# Cortex_M0 register map
Vendor: ARM Ltd.; File version: 1.1
Cortex-M0 core descriptions, generated from ARM develloper studio
CPU: CM0 r0p0, little endian, no MPU, no FPU, vendor SysTick, 8 interrupt priority bits
Registers are 32-bit, read-write, no defined reset value unless marked. A register's access mark holds for its fields unless they carry their own. Offsets are from the block's base; lines under a group give offsets from that group; [hi:lo] are bit positions; {n}, {i} and the like mark numbered series; 'fields as' and 'values as' point back to an identical list; <NAME> marks a mode.

## Memory map
0xE000E010 SysTick size 0x80 — System Timer registers
0xE000E100 NVIC size 0x1A0 — Nested Vectored Interrupt Controller registers
0xE000ED00 ID size 0x20 — ID registers
0xE000ED04 Control size 0xC0 — System Control registers

## Control — System Control registers
Base 0xE000ED04
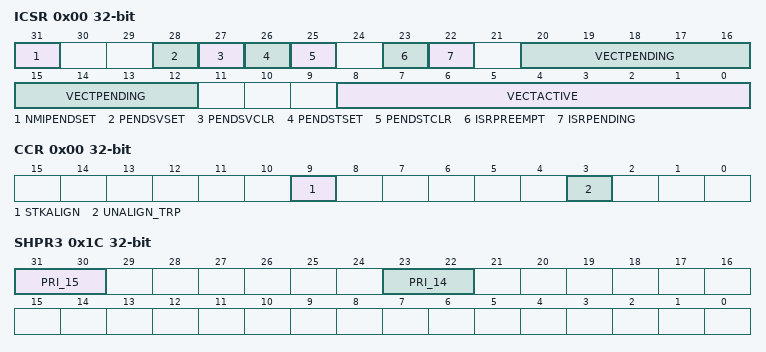
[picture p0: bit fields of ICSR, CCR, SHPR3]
0x00 ICSR
  [31] NMIPENDSET
    0=Do_not_activate; 1=Activate_NMI_exception
  [28] PENDSVSET
    0=Do_not_set; 1=Set_pending
  [27] PENDSVCLR
    0=Do_not_clear; 1=Clear_pending
  [26] PENDSTSET
    0=Do_not_set; 1=Set_pending
  [25] PENDSTCLR
    0=Do_not_clear; 1=Clear_pending
  [23] ISRPREEMPT
    0=Will_not_service; 1=Will_service_pending_exception
  [22] ISRPENDING
    0=Interrupt_not_pending; 1=Interrupt_pending
  [20:12] VECTPENDING
  [8:0] VECTACTIVE
0x00 CCR ro
  [9] STKALIGN, [3] UNALIGN_TRP
0x08 AIRCR
  [31:16] VECTKEY
  [31:16] VECTKEYSTAT
  [15] ENDIANNESS
    0=Little_endian; 1=Big_endian
  [2] SYSRESETREQ
    0=Do_not_request_reset; 1=Request_reset
  [1] VECTCLRACTIVE
    0=Do_not_clear; 1=Clear_state_information
0x18 SHPR2
  [31:30] PRI_11
0x1C SHPR3
  [31:30] PRI_15, [23:22] PRI_14
0x20 SHCSR
  [15] SVCALLPENDED
    0=Not_pending; 1=Pending

## ID — ID registers
Base 0xE000ED00
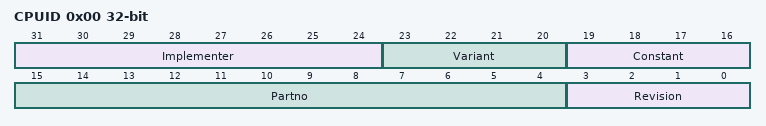
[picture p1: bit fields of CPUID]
0x00 CPUID ro
  [31:24] Implementer, [23:20] Variant, [19:16] Constant, [15:4] Partno, [3:0] Revision

## NVIC — Nested Vectored Interrupt Controller registers
Base 0xE000E100
0x00 NVIC_ISER0
0x00 NVIC_ISPR0
0x80 NVIC_ICER0
0x180 NVIC_ICPR0
0x200 NVIC_IABR0
{0x300+4i} NVIC_IPR{i} (i=0..7)

## SysTick — System Timer registers
Base 0xE000E010
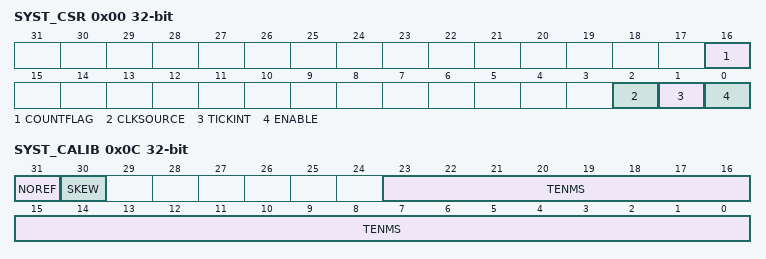
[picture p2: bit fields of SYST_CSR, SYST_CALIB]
0x00 SYST_CSR
  [16] COUNTFLAG
    0=not_counted_to_0; 1=counted_to_0
  [2] CLKSOURCE
    0=External_clock; 1=Processor_clock
  [1] TICKINT
    0=Does_not_affect_exception_status; 1=Changes_exception_status
  [0] ENABLE
    0=Counter_disabled; 1=Counter_operating
0x04 SYST_RVR
  [23:0] RELOAD
0x08 SYST_CVR
  [23:0] CURRENT
0x0C SYST_CALIB
  [31] NOREF
    0=Implemented; 1=Not_implemented
  [30] SKEW
    0=Exact; 1=Inexact
  [23:0] TENMS

## Notices in the file
Copyright (c) 2020 STMicroelectronics.
SPDX-License-Identifier: Apache-2.0
Licensed under the Apache License, Version 2.0 (the "License");
you may not use this file except in compliance with the License.
You may obtain a copy of the License at
http://www.apache.org/licenses/LICENSE-2.0
Unless required by applicable law or agreed to in writing, software
distributed under the License is distributed on an "AS IS" BASIS,
WITHOUT WARRANTIES OR CONDITIONS OF ANY KIND, either express or implied.
See the License for the specific language governing permissions and
limitations under the License.
